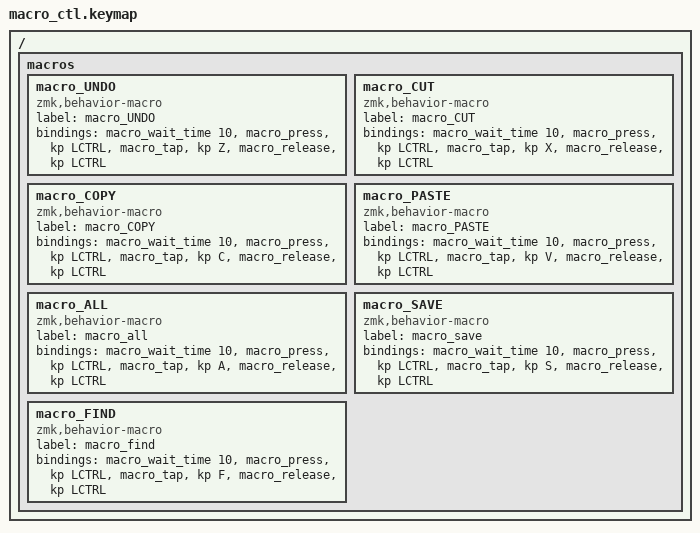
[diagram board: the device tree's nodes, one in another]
/ {
    macros {
       macro_UNDO: macro_UNDO {
            label = "macro_UNDO";
            compatible = "zmk,behavior-macro";
            #binding-cells = <0>;
            bindings
                = <&macro_wait_time 10>
                , <&macro_press &kp LCTRL>
                , <&macro_tap &kp Z>
                , <&macro_release &kp LCTRL>
                ;
        };
        macro_CUT: macro_CUT {
            label = "macro_CUT";
            compatible = "zmk,behavior-macro";
            #binding-cells = <0>;
            bindings
                = <&macro_wait_time 10>
                , <&macro_press &kp LCTRL>
                , <&macro_tap &kp X>
                , <&macro_release &kp LCTRL>
                ;
        };
        macro_COPY: macro_COPY {
            label = "macro_COPY";
            compatible = "zmk,behavior-macro";
            #binding-cells = <0>;
            bindings
                = <&macro_wait_time 10>
                , <&macro_press &kp LCTRL>
                , <&macro_tap &kp C>
                , <&macro_release &kp LCTRL>
                ;
        };
        macro_PASTE: macro_PASTE {
            label = "macro_PASTE";
            compatible = "zmk,behavior-macro";
            #binding-cells = <0>;
            bindings
                = <&macro_wait_time 10>
                , <&macro_press &kp LCTRL>
                , <&macro_tap &kp V>
                , <&macro_release &kp LCTRL>
                ;
        };
        macro_ALL: macro_ALL {
            label = "macro_all";
            compatible = "zmk,behavior-macro";
            #binding-cells = <0>;
            bindings
                = <&macro_wait_time 10>
                , <&macro_press &kp LCTRL>
                , <&macro_tap &kp A>
                , <&macro_release &kp LCTRL>
                ;
        };
        macro_SAVE: macro_SAVE {
            label = "macro_save";
            compatible = "zmk,behavior-macro";
            #binding-cells = <0>;
            bindings
                = <&macro_wait_time 10>
                , <&macro_press &kp LCTRL>
                , <&macro_tap &kp S>
                , <&macro_release &kp LCTRL>
                ;
        };
        macro_FIND: macro_FIND {
            label = "macro_find";
            compatible = "zmk,behavior-macro";
            #binding-cells = <0>;
            bindings
                = <&macro_wait_time 10>
                , <&macro_press &kp LCTRL>
                , <&macro_tap &kp F>
                , <&macro_release &kp LCTRL>
                ;
        };
   };
};
